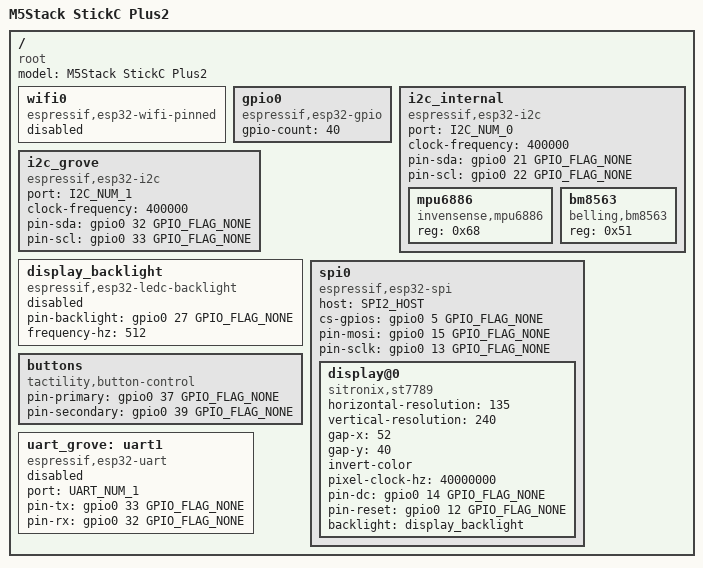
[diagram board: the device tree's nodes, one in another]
/dts-v1/;
#include <tactility/bindings/root.h>
#include <tactility/bindings/esp32_wifi_pinned.h>
#include <tactility/bindings/esp32_gpio.h>
#include <tactility/bindings/esp32_i2c.h>
#include <tactility/bindings/esp32_spi.h>
#include <tactility/bindings/esp32_uart.h>
#include <bindings/mpu6886.h>
#include <bindings/bm8563.h>
#include <tactility/bindings/esp32_ledc_backlight.h>

#include <bindings/st7789.h>
#include <bindings/button_control.h>

/ {
	compatible = "root";
	model = "M5Stack StickC Plus2";

	wifi0 {
		compatible = "espressif,esp32-wifi-pinned";
		status = "disabled";
	};

	gpio0 {
		compatible = "espressif,esp32-gpio";
		gpio-count = <40>;
	};

	i2c_internal {
		compatible = "espressif,esp32-i2c";
		port = <I2C_NUM_0>;
		clock-frequency = <400000>;
		pin-sda = <&gpio0 21 GPIO_FLAG_NONE>;
		pin-scl = <&gpio0 22 GPIO_FLAG_NONE>;

		mpu6886 {
			compatible = "invensense,mpu6886";
			reg = <0x68>;
		};

		bm8563 {
			compatible = "belling,bm8563";
			reg = <0x51>;
		};
	};

	i2c_grove {
		compatible = "espressif,esp32-i2c";
		port = <I2C_NUM_1>;
		clock-frequency = <400000>;
		pin-sda = <&gpio0 32 GPIO_FLAG_NONE>;
		pin-scl = <&gpio0 33 GPIO_FLAG_NONE>;
	};

	display_backlight {
		compatible = "espressif,esp32-ledc-backlight";
		// Off by default so display power-on won't show the screen from before the last power loss.
		// The display backlight is turned on during the boot process.
		status = "disabled";
		pin-backlight = <&gpio0 27 GPIO_FLAG_NONE>;
		frequency-hz = <512>;
	};

	spi0 {
		compatible = "espressif,esp32-spi";
		host = <SPI2_HOST>;
		cs-gpios = <&gpio0 5 GPIO_FLAG_NONE>;
		pin-mosi = <&gpio0 15 GPIO_FLAG_NONE>;
		pin-sclk = <&gpio0 13 GPIO_FLAG_NONE>;

		display@0 {
			compatible = "sitronix,st7789";
			horizontal-resolution = <135>;
			vertical-resolution = <240>;
			gap-x = <52>;
			gap-y = <40>;
			invert-color;
			pixel-clock-hz = <40000000>;
			pin-dc = <&gpio0 14 GPIO_FLAG_NONE>;
			pin-reset = <&gpio0 12 GPIO_FLAG_NONE>;
			backlight = <&display_backlight>;
		};
	};

	buttons {
		compatible = "tactility,button-control";
		pin-primary = <&gpio0 37 GPIO_FLAG_NONE>;
		pin-secondary = <&gpio0 39 GPIO_FLAG_NONE>;
	};

	uart_grove: uart1 {
		compatible = "espressif,esp32-uart";
		status = "disabled";
		port = <UART_NUM_1>;
		pin-tx = <&gpio0 33 GPIO_FLAG_NONE>;
		pin-rx = <&gpio0 32 GPIO_FLAG_NONE>;
	};
};
